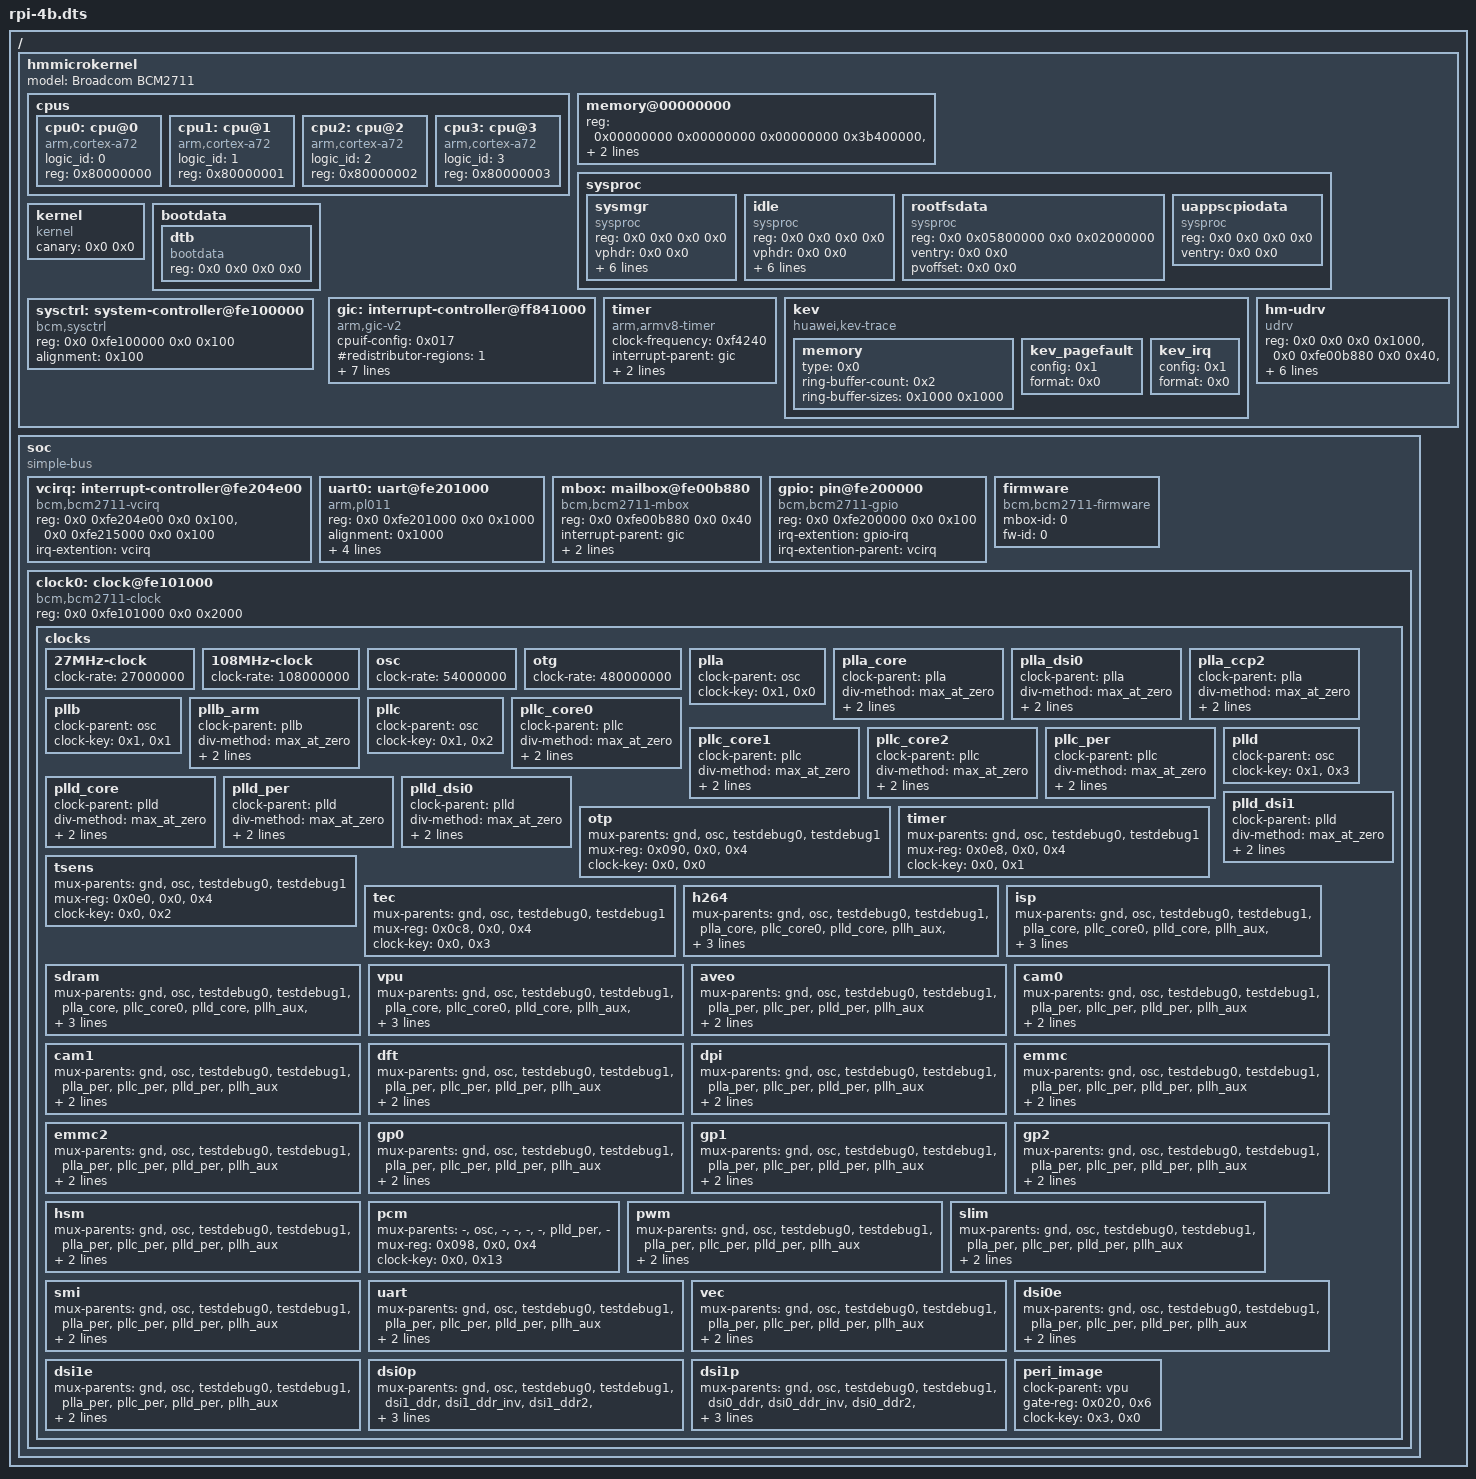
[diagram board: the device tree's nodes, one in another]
/dts-v1/;
/ {
	#address-cells = <2>;
	#size-cells = <2>;
	hmmicrokernel {
		#address-cells = <2>;
		#size-cells = <2>;
		model = "Broadcom BCM2711";
		cpus {
			#address-cells = <1>;
			#size-cells = <0>;
			cpu0: cpu@0 {
				compatible = "arm,cortex-a72", "arm,armv8";
				device_type = "cpu";
				logic_id = <0>;
				reg = <0x80000000>;
			};
			cpu1: cpu@1 {
				compatible = "arm,cortex-a72", "arm,armv8";
				device_type = "cpu";
				logic_id = <1>;
				reg = <0x80000001>;
			};
			cpu2: cpu@2 {
				compatible = "arm,cortex-a72", "arm,armv8";
				device_type = "cpu";
				logic_id = <2>;
				reg = <0x80000002>;
			};
			cpu3: cpu@3 {
				compatible = "arm,cortex-a72", "arm,armv8";
				device_type = "cpu";
				logic_id = <3>;
				reg = <0x80000003>;
			};
		};

		memory@00000000 {
			device_type = "memory";
			reg = <0x00000000 0x00000000 0x00000000 0x3b400000>,
			      <0x00000000 0x40000000 0x00000000 0xbc000000>,
			      <0x00000001 0x00000000 0x00000001 0x00000000>;
		};

		sysproc {
			#address-cells = <2>;
			#size-cells = <2>;
			sysmgr {
				compatible = "sysproc", "sysmgr";
				/* filled by bootloader */
				reg      = <0x0 0x0 0x0 0x0>;
				vphdr    = <0x0 0x0>;
				ventry   = <0x0 0x0>;
				pvoffset = <0x0 0x0>;
				nphdrs   = <0>;
				stack_start = <0x0 0x0>;
				stack_end = <0x0 0x0>;
				canary = <0x0 0x0>;
			};
			idle {
				compatible = "sysproc", "idle";
				/* filled by bootloader */
				reg      = <0x0 0x0 0x0 0x0>;
				vphdr    = <0x0 0x0>;
				ventry   = <0x0 0x0>;
				pvoffset = <0x0 0x0>;
				nphdrs   = <0>;
				stack_start = <0x0 0x0>;
				stack_end = <0x0 0x0>;
				canary = <0x0 0x0>;
			};
			rootfsdata {
				compatible = "sysproc", "rootfs";
				/* filled by bootloader */
				reg      = <0x0 0x05800000 0x0 0x02000000>;
				ventry   = <0x0 0x0>;
				pvoffset = <0x0 0x0>;
			};
			uappscpiodata {
				compatible = "sysproc", "uappscpio";
				/* filled by bootloader */
				reg      = <0x0 0x0 0x0 0x0>;
				ventry   = <0x0 0x0>;
			};
		};

		kernel {
			compatible = "kernel";
			/* filled by bootloader */
			canary = <0x0 0x0>;
		};

		bootdata {
			#address-cells = <2>;
			#size-cells = <2>;
			dtb {
				compatible = "bootdata", "dtb";
				/* filled by bootloader */
				reg = <0x0 0x0 0x0 0x0>;
			};
		};

		gic: interrupt-controller@ff841000 {
			compatible = "arm,gic-v2", "arm,gic-400";

			#address-cells = <2>;
			#size-cells = <2>;

			cpuif-config = <0x017>;

			#interrupt-cells = <3>;
			#redistributor-regions = <1>;
			redistributor-stride = <0x2000>;
			interrupt-controller;
			reg =   <0x0 0xff841000 0x0 0x1000>,
			        <0x0 0xff842000 0x0 0x2000>,  /* cpu intf */
			        <0x0 0xff844000 0x0 0x2000>,  /* hypervisor */
			        <0x0 0xff846000 0x0 0x2000>;  /* virtual cpu */
			alignment = <0x1000 0x1000 0x1000 0x1000>;
		};

		timer {
			compatible = "arm,armv8-timer";
			clock-frequency = <0xf4240>;

			/* interrupt settings */
			interrupt-parent = <&gic>;

			/* PPI 30: Non-secure physical timer
			* level triggered, hwprio:2 */
			interrupts = <30 0x000000E0 0xFFFFFFFF>,
			             <26 0x000000E0 0xFFFFFFFF>;
		};

		kev {
			compatible = "huawei,kev-trace";

			memory {
				type = <0x0>;
				ring-buffer-count = <0x2>;
				ring-buffer-sizes = <0x1000 0x1000>;
			};
			kev_pagefault {
				config = <0x1>;
				format = <0x0>;
			};
			kev_irq {
				config = <0x1>;
				format = <0x0>;
			};
		};

		hm-udrv {
			compatible = "udrv";
			reg = <0x0 0x0 0x0 0x1000>,
			      <0x0 0xfe00b880 0x0 0x40>,
			      <0x0 0xfe100000 0x0 0x100>,
			      <0x0 0xfe101000 0x0 0x2000>, /* clock0 */
			      <0x0 0xfe200000 0x0 0x100>,
			      <0x0 0xfe201000 0x0 0x1000>,
			      <0x0 0xfe204e00 0x0 0x100>,
			      <0x0 0xfe215000 0x0 0x100>;
		};

		sysctrl: system-controller@fe100000 {
			compatible = "bcm,sysctrl";
			reg = <0x0 0xfe100000 0x0 0x100>;
			alignment = <0x100>;
		};
	};

	soc {
		compatible = "simple-bus";
		#address-cells = <2>;
		#size-cells = <2>;
		ranges;

		vcirq: interrupt-controller@fe204e00 {
			compatible = "bcm,bcm2711-vcirq";
			reg = <0x0 0xfe204e00 0x0 0x100>,
			      <0x0 0xfe215000 0x0 0x100>;
			irq-extention = "vcirq";
		};

		uart0: uart@fe201000 {
			compatible = "arm,pl011", "arm,pl011,uart";
			reg = <0x0 0xfe201000 0x0 0x1000>;
			alignment = <0x1000>;

			/* kernel control input */
			kernel-input;
			fifo-enabled;

			interrupt-parent = <&gic>;
			interrupts = <153 0x000000E0 0x00000001>;
		};

		mbox: mailbox@fe00b880 {
			compatible = "bcm,bcm2711-mbox";
			reg = <0x0 0xfe00b880 0x0 0x40>;
			interrupt-parent = <&gic>;
			interrupts = <65 0x000000E0 0x00000001>;
			mbox-id = <0>;
		};

		gpio: pin@fe200000 {
			compatible = "bcm,bcm2711-gpio";
			reg = <0x0 0xfe200000 0x0 0x100>;
			irq-extention = "gpio-irq";
			irq-extention-parent = "vcirq";
		};

		firmware {
			compatible = "bcm,bcm2711-firmware";
			mbox-id = <0>;
			fw-id = <0>;
		};

		clock0: clock@fe101000 {
			compatible = "bcm,bcm2711-clock";
			reg = <0x0 0xfe101000 0x0 0x2000>;

			clocks {
				27MHz-clock {
					clock-rate = <27000000>;
				};
				108MHz-clock {
					clock-rate = <108000000>;
				};
				osc {
					clock-rate = <54000000>;
				};
				otg {
					clock-rate = <480000000>;
				};
				plla {
					clock-parent = "osc";
					clock-key = <0x1>, <0x0>;
				};
				plla_core {
					clock-parent = "plla";
					div-method = "max_at_zero";
					div-reg = <0x1400>, <0x0>, <0x8>;
					clock-key = <0x2>, <0x0>;
				};
				plla_dsi0 {
					clock-parent = "plla";
					div-method = "max_at_zero";
					div-reg = <0x1300>, <0x0>, <0x8>;
					clock-key = <0x2>, <0x1>;
				};
				plla_ccp2 {
					clock-parent = "plla";
					div-method = "max_at_zero";
					div-reg = <0x1600>, <0x0>, <0x8>;
					clock-key = <0x2>, <0x2>;
				};
				pllb {
					clock-parent = "osc";
					clock-key = <0x1>, <0x1>;
				};
				pllb_arm {
					clock-parent = "pllb";
					div-method = "max_at_zero";
					div-reg = <0x13e0>, <0x0>, <0x8>;
					clock-key = <0x2>, <0x3>;
				};
				pllc {
					clock-parent = "osc";
					clock-key = <0x1>, <0x2>;
				};
				pllc_core0 {
					clock-parent = "pllc";
					div-method = "max_at_zero";
					div-reg = <0x1620>, <0x0>, <0x8>;
					clock-key = <0x2>, <0x4>;
				};
				pllc_core1 {
					clock-parent = "pllc";
					div-method = "max_at_zero";
					div-reg = <0x1420>, <0x0>, <0x8>;
					clock-key = <0x2>, <0x5>;
				};
				pllc_core2 {
					clock-parent = "pllc";
					div-method = "max_at_zero";
					div-reg = <0x1320>, <0x0>, <0x8>;
					clock-key = <0x2>, <0x6>;
				};
				pllc_per {
					clock-parent = "pllc";
					div-method = "max_at_zero";
					div-reg = <0x1520>, <0x0>, <0x8>;
					clock-key = <0x2>, <0x7>;
				};
				plld {
					clock-parent = "osc";
					clock-key = <0x1>, <0x3>;
				};
				plld_core {
					clock-parent = "plld";
					div-method = "max_at_zero";
					div-reg = <0x1440>, <0x0>, <0x8>;
					clock-key = <0x2>, <0x8>;
				};
				plld_per {
					clock-parent = "plld";
					div-method = "max_at_zero";
					div-reg = <0x1540>, <0x0>, <0x8>;
					clock-key = <0x2>, <0x9>;
				};
				plld_dsi0 {
					clock-parent = "plld";
					div-method = "max_at_zero";
					div-reg = <0x1340>, <0x0>, <0x8>;
					clock-key = <0x2>, <0xa>;
				};
				plld_dsi1 {
					clock-parent = "plld";
					div-method = "max_at_zero";
					div-reg = <0x1640>, <0x0>, <0x8>;
					clock-key = <0x2>, <0xb>;
				};
				otp {
					mux-parents = "gnd", "osc", "testdebug0",
						      "testdebug1";
					mux-reg = <0x090>, <0x0>, <0x4>;
					clock-key = <0x0>, <0x0>;
				};
				timer {
					mux-parents = "gnd", "osc", "testdebug0",
						      "testdebug1";
					mux-reg = <0x0e8>, <0x0>, <0x4>;
					clock-key = <0x0>, <0x1>;
				};
				tsens {
					mux-parents = "gnd", "osc", "testdebug0",
						      "testdebug1";
					mux-reg = <0x0e0>, <0x0>, <0x4>;
					clock-key = <0x0>, <0x2>;
				};
				tec {
					mux-parents = "gnd", "osc", "testdebug0",
						      "testdebug1";
					mux-reg = <0x0c8>, <0x0>, <0x4>;
					clock-key = <0x0>, <0x3>;
				};
				h264 {
					mux-parents = "gnd", "osc", "testdebug0",
						      "testdebug1", "plla_core",
						      "pllc_core0", "plld_core",
						      "pllh_aux", "pllc_core1",
						      "pllc_core2";
					mux-reg = <0x028>, <0x0>, <0x4>;
					clock-key = <0x0>, <0x4>;
				};
				isp {
					mux-parents = "gnd", "osc", "testdebug0",
						      "testdebug1", "plla_core",
						      "pllc_core0", "plld_core",
						      "pllh_aux", "pllc_core1",
						      "pllc_core2";
					mux-reg = <0x030>, <0x0>, <0x4>;
					clock-key = <0x0>, <0x5>;
				};
				sdram {
					mux-parents = "gnd", "osc", "testdebug0",
						      "testdebug1", "plla_core",
						      "pllc_core0", "plld_core",
						      "pllh_aux", "pllc_core1",
						      "pllc_core2";
					mux-reg = <0x1a8>, <0x0>, <0x4>;
					clock-key = <0x0>, <0x6>;
				};
				vpu {
					mux-parents = "gnd", "osc", "testdebug0",
					      "testdebug1", "plla_core",
					      "pllc_core0", "plld_core",
					      "pllh_aux", "pllc_core1",
					      "pllc_core2";
					mux-reg = <0x008>, <0x0>, <0x4>;
					clock-key = <0x0>, <0x7>;
				};
				aveo {
					mux-parents = "gnd", "osc", "testdebug0",
						      "testdebug1", "plla_per",
						      "pllc_per", "plld_per",
						      "pllh_aux";
					mux-reg = <0x1b8>, <0x0>, <0x4>;
					clock-key = <0x0>, <0x8>;
				};
				cam0 {
					mux-parents = "gnd", "osc", "testdebug0",
						      "testdebug1", "plla_per",
						      "pllc_per", "plld_per",
						      "pllh_aux";
					mux-reg = <0x040>, <0x0>, <0x4>;
					clock-key = <0x0>, <0x9>;
				};
				cam1 {
					mux-parents = "gnd", "osc", "testdebug0",
						      "testdebug1", "plla_per",
						      "pllc_per", "plld_per",
						      "pllh_aux";
					mux-reg = <0x048>, <0x0>, <0x4>;
					clock-key = <0x0>, <0xa>;
				};
				dft {
					mux-parents = "gnd", "osc", "testdebug0",
						      "testdebug1", "plla_per",
						      "pllc_per", "plld_per",
						      "pllh_aux";
					mux-reg = <0x168>, <0x0>, <0x4>;
					clock-key = <0x0>, <0xb>;
				};
				dpi {
					mux-parents = "gnd", "osc", "testdebug0",
						      "testdebug1", "plla_per",
						      "pllc_per", "plld_per",
						      "pllh_aux";
					mux-reg = <0x068>, <0x0>, <0x4>;
					clock-key = <0x0>, <0xc>;
				};
				emmc {
					mux-parents = "gnd", "osc", "testdebug0",
						      "testdebug1", "plla_per",
						      "pllc_per", "plld_per",
						      "pllh_aux";
					mux-reg = <0x1c0>, <0x0>, <0x4>;
					clock-key = <0x0>, <0xd>;
				};
				emmc2 {
					mux-parents = "gnd", "osc", "testdebug0",
						      "testdebug1", "plla_per",
						      "pllc_per", "plld_per",
						      "pllh_aux";
					mux-reg = <0x1d0>, <0x0>, <0x4>;
					clock-key = <0x0>, <0xe>;
				};
				gp0 {
					mux-parents = "gnd", "osc", "testdebug0",
						      "testdebug1", "plla_per",
						      "pllc_per", "plld_per",
						      "pllh_aux";
					mux-reg = <0x070>, <0x0>, <0x4>;
					clock-key = <0x0>, <0xf>;
				};
				gp1 {
					mux-parents = "gnd", "osc", "testdebug0",
						      "testdebug1", "plla_per",
						      "pllc_per", "plld_per",
						      "pllh_aux";
					mux-reg = <0x078>, <0x0>, <0x4>;
					clock-key = <0x0>, <0x10>;
				};
				gp2 {
					mux-parents = "gnd", "osc", "testdebug0",
						      "testdebug1", "plla_per",
						      "pllc_per", "plld_per",
						      "pllh_aux";
					mux-reg = <0x080>, <0x0>, <0x4>;
					clock-key = <0x0>, <0x11>;
				};
				hsm {
					mux-parents = "gnd", "osc", "testdebug0",
						      "testdebug1", "plla_per",
						      "pllc_per", "plld_per",
						      "pllh_aux";
					mux-reg = <0x088>, <0x0>, <0x4>;
					clock-key = <0x0>, <0x12>;
				};
				pcm {
					mux-parents = "-", "osc", "-", "-", "-",
						      "-", "plld_per", "-";
					mux-reg = <0x098>, <0x0>, <0x4>;
					clock-key = <0x0>, <0x13>;
				};
				pwm {
					mux-parents = "gnd", "osc", "testdebug0",
						      "testdebug1", "plla_per",
						      "pllc_per", "plld_per",
						      "pllh_aux";
					mux-reg = <0x0a0>, <0x0>, <0x4>;
					clock-key = <0x0>, <0x14>;
				};
				slim {
					mux-parents = "gnd", "osc", "testdebug0",
						      "testdebug1", "plla_per",
						      "pllc_per", "plld_per",
						      "pllh_aux";
					mux-reg = <0x0a8>, <0x0>, <0x4>;
					clock-key = <0x0>, <0x15>;
				};
				smi {
					mux-parents = "gnd", "osc", "testdebug0",
						      "testdebug1", "plla_per",
						      "pllc_per", "plld_per",
						      "pllh_aux";
					mux-reg = <0x0b0>, <0x0>, <0x4>;
					clock-key = <0x0>, <0x16>;
				};
				uart {
					mux-parents = "gnd", "osc", "testdebug0",
						      "testdebug1", "plla_per",
						      "pllc_per", "plld_per",
						      "pllh_aux";
					mux-reg = <0x0f0>, <0x0>, <0x4>;
					clock-key = <0x0>, <0x17>;
				};
				vec {
					mux-parents = "gnd", "osc", "testdebug0",
						      "testdebug1", "plla_per",
						      "pllc_per", "plld_per",
						      "pllh_aux";
					mux-reg = <0x0f8>, <0x0>, <0x4>;
					clock-key = <0x0>, <0x18>;
				};
				dsi0e {
					mux-parents = "gnd", "osc", "testdebug0",
						      "testdebug1", "plla_per",
						      "pllc_per", "plld_per",
						      "pllh_aux";
					mux-reg = <0x058>, <0x0>, <0x4>;
					clock-key = <0x0>, <0x19>;
				};
				dsi1e {
					mux-parents = "gnd", "osc", "testdebug0",
						      "testdebug1", "plla_per",
						      "pllc_per", "plld_per",
						      "pllh_aux";
					mux-reg = <0x158>, <0x0>, <0x4>;
					clock-key = <0x0>, <0x1a>;
				};
				dsi0p {
					mux-parents = "gnd", "osc", "testdebug0",
						      "testdebug1", "dsi1_ddr",
						      "dsi1_ddr_inv", "dsi1_ddr2",
						      "dsi1_ddr2_inv", "dsi1_byte",
						      "dsi1_byte_inv";
					mux-reg = <0x060>, <0x0>, <0x4>;
					clock-key = <0x0>, <0x1b>;
				};
				dsi1p {
					mux-parents = "gnd", "osc", "testdebug0",
						      "testdebug1", "dsi0_ddr",
						      "dsi0_ddr_inv", "dsi0_ddr2",
						      "dsi0_ddr2_inv", "dsi0_byte",
						      "dsi0_byte_inv";
					mux-reg = <0x160>, <0x0>, <0x4>;
					clock-key = <0x0>, <0x1c>;
				};
				peri_image {
					clock-parent = "vpu";
					gate-reg = <0x020>, <0x6>;
					clock-key = <0x3>, <0x0>;
				};
			};
		};
	};
};
